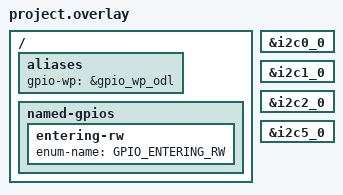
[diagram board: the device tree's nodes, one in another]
/* Copyright 2025 The ChromiumOS Authors
 * Use of this source code is governed by a BSD-style license that can be
 * found in the LICENSE file.
 */

/* ocelot program common DTS includes */

#include <cros/integrated_fwid.dtsi>

/* ocelot_nuvoton project DTS includes */
#include "generated.dtsi"

/*
 * Map I2C buses to common names
 */

i2c_port_pd1: &i2c0_0 {
};

i2c_port_pd2: &i2c1_0 {
};

i2c_port_charger: &i2c2_0 {
};

i2c_port_ish: &i2c5_0 {
};


#include "../rvp_i2c.dtsi"

/* ocelot_nuvoton overrides follow... */
/ {
	aliases {
		gpio-wp = &gpio_wp_odl;
	};

	named-gpios {
		/* unimplemented GPIOs */
		entering-rw {
			enum-name = "GPIO_ENTERING_RW";
		};
	};
};


/* Disable nodes for features not yet enabled. */
/delete-node/ &{/named-adc-channels};
